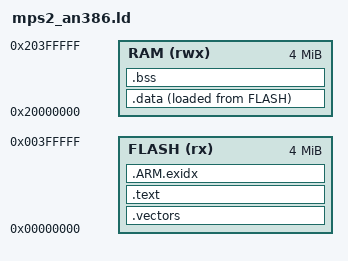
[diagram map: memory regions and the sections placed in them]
ENTRY(Reset_Handler)

MEMORY
{
    FLASH (rx)  : ORIGIN = 0x00000000, LENGTH = 4M
    RAM   (rwx) : ORIGIN = 0x20000000, LENGTH = 4M
}

__stack_top = ORIGIN(RAM) + LENGTH(RAM);

SECTIONS
{
    .vectors ORIGIN(FLASH) :
    {
        KEEP(*(.vectors))
    } > FLASH

    .text :
    {
        *(.text.Reset_Handler*)
        *(.text*)
        *(.rodata*)
        *(.ARM.extab*)
    } > FLASH

    .ARM.exidx :
    {
        __exidx_start = .;
        *(.ARM.exidx* .gnu.linkonce.armexidx.*)
        __exidx_end = .;
    } > FLASH

    .data :
    {
        . = ALIGN(4);
        __data_start = .;
        *(.data*)
        . = ALIGN(4);
        __data_end = .;
    } > RAM AT > FLASH

    .bss (NOLOAD) :
    {
        . = ALIGN(4);
        __bss_start = .;
        *(.bss*)
        *(COMMON)
        . = ALIGN(4);
        __bss_end = .;
    } > RAM
}
